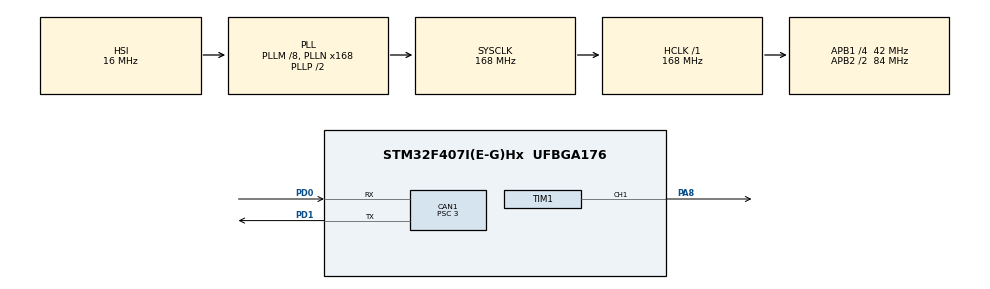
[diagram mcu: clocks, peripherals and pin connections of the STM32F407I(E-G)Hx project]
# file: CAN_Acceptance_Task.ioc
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CAN1.ABOM=ENABLE
CAN1.BS1=CAN_BS1_12TQ
CAN1.CalculateBaudRate=1000000
CAN1.CalculateTimeBit=1000
CAN1.CalculateTimeQuantum=71.42857142857143
CAN1.Prescaler=3
Mcu.Family=STM32F4
Mcu.Name=STM32F407I(E-G)Hx
Mcu.Package=UFBGA176
NVIC.CAN1_RX0_IRQn=true\:0\:0\:false\:false\:true\:true\:true\:true
NVIC.CAN1_TX_IRQn=true\:0\:0\:false\:false\:true\:true\:true\:true
NVIC.PriorityGroup=NVIC_PRIORITYGROUP_4
PA13.Mode=Serial_Wire
PA13.Signal=SYS_JTMS-SWDIO
PA14.Mode=Serial_Wire
PA14.Signal=SYS_JTCK-SWCLK
PA8.Signal=S_TIM1_CH1
PD0.Mode=CAN_Activate
PD0.Signal=CAN1_RX
PD1.Mode=CAN_Activate
PD1.Signal=CAN1_TX
PH0-OSC_IN.Mode=HSE-External-Oscillator
PH0-OSC_IN.Signal=RCC_OSC_IN
PH1-OSC_OUT.Mode=HSE-External-Oscillator
PH1-OSC_OUT.Signal=RCC_OSC_OUT
ProjectManager.HeapSize=0x200
ProjectManager.StackSize=0x400
ProjectManager.TargetToolchain=MDK-ARM V5.32
RCC.48MHZClocksFreq_Value=84000000
RCC.AHBFreq_Value=168000000
RCC.APB1CLKDivider=RCC_HCLK_DIV4
RCC.APB1Freq_Value=42000000
RCC.APB1TimFreq_Value=84000000
RCC.APB2CLKDivider=RCC_HCLK_DIV2
RCC.APB2Freq_Value=84000000
RCC.APB2TimFreq_Value=168000000
RCC.CortexFreq_Value=168000000
RCC.HCLKFreq_Value=168000000
RCC.HSE_VALUE=25000000
RCC.HSI_VALUE=16000000
RCC.LSE_VALUE=32768
RCC.PLLM=8
RCC.PLLN=168
RCC.SYSCLKFreq_VALUE=168000000
RCC.SYSCLKSource=RCC_SYSCLKSOURCE_PLLCLK
RCC.VCOOutputFreq_Value=336000000
SH.S_TIM1_CH1.0=TIM1_CH1,PWM Generation1 CH1
TIM1.Channel-PWM\ Generation1\ CH1=TIM_CHANNEL_1
VP_TIM1_VS_ClockSourceINT.Mode=Internal
board=custom

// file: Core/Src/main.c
/* USER CODE BEGIN Header */
/**
  ******************************************************************************
  * @file           : main.c
  * @brief          : Main program body
  ******************************************************************************
  * @attention
  *
  * Copyright (c) 2026 STMicroelectronics.
  * All rights reserved.
  *
  * This software is licensed under terms that can be found in the LICENSE file
  * in the root directory of this software component.
  * If no LICENSE file comes with this software, it is provided AS-IS.
  *
  ******************************************************************************
  */
/* USER CODE END Header */
#include "main.h"
#include "can.h"
#include "tim.h"
#include "gpio.h"

/* USER CODE BEGIN Includes */
#include "gm6020.h"
#include "pid.h"
#include "math.h"
/* USER CODE END Includes */

/* USER CODE BEGIN PD */
#define USE_FIXED_SPEED // 定义这个宏, 使用固定速度测试PID控制器; 注释掉这个宏, 使用正弦函数模拟目标速度的变化, 测试PID控制器在动态目标下的表现
#define INTERGRAL_MAX 10000.0f // PID积分限幅
#define OUTPUT_MAX 50000.0f // PID输出限幅

/* PID参数设置 */
#define KP 15.0f // 比例增益
#define KI 1.0f // 积分增益
#define KD 0.00f // 微分增益
/* 控制周期（单位：ms）
 * 建议1ms，和电机反馈频率匹配
 * 如果改这个值，Ki需要同步调整（Ki_new = Ki_old × 新周期/旧周期）*/
#define CONTROL_PERIOD  1

/* USER CODE END PD */

/* USER CODE BEGIN PV */
PID_T pid_speed; // 定义一个PID控制器实例, 用于速度控制
  float target_speed = 0.0f; // 目标速度, 单位为RPM

/* USER CODE END PV */

void SystemClock_Config(void);

/* USER CODE BEGIN 0 */
float Target_Speed_Sin( )
{
  /* 模拟正弦波 */
  float frequency = 50.0f;
  float result = 100.0f * sin( 2.0f * 3.14f * frequency * ( HAL_GetTick() ) / 1000.0f );
  return result;
}
/* USER CODE END 0 */

int main(void)
{

  /* MCU Configuration--------------------------------------------------------*/

  /* Reset of all peripherals, Initializes the Flash interface and the Systick. */
  HAL_Init();

  /* Configure the system clock */
  SystemClock_Config();

  /* Initialize all configured peripherals */
  MX_GPIO_Init();
  MX_CAN1_Init();
  MX_TIM1_Init();
  /* USER CODE BEGIN 2 */
  GM6020_CAN_Init(); // CAN初始化, 内部完成配置滤波器, 使能CAN, 开启中断回调
  PID_Init(&pid_speed, KP, KI, KD, INTERGRAL_MAX, OUTPUT_MAX); // 初始化PID控制器
  uint8_t flag = 1;
  /* USER CODE END 2 */

  /* Infinite loop */
  /* USER CODE BEGIN WHILE */
  while (1)
  {

    // GM6020_Set_Voltage_5TO7(3000, 3000, 3000); // 测试一下是否能够正常控制电机电压

    // GM6020_Set_Voltage_1TO4(0, 3000, 3000, 3000); // 测试一下是否能够正常控制电机电压
    if( GM6020_IsOnline(1, 500) == OFFLINE ) flag = 0; // 检测电机是否在线, flag = 0 表示电机不在线, flag = 1 表示电机在线
    else flag = 1;
    float actual_speed = (float)gm6020[1].speed; // 获取电机1的实际速度, 单位为RPM
#ifdef USE_FIXED_SPEED
    target_speed = 100.0f; // 固定目标速度
#else
    target_speed = Target_Speed_Sin(); // 模拟正弦波作为目标速度
#endif
    float voltage = PID_Calculate(&pid_speed, target_speed, actual_speed); // 计算PID控制器输出的电压值
    GM6020_Set_Voltage_1TO4(voltage, 0 ,0, voltage); // 输出电压控制电机1, 电机2-4不控制
    HAL_Delay(CONTROL_PERIOD); // 控制周期, 建议1ms, 和电机反馈频率匹配
    /* USER CODE END WHILE */

  }
}

void SystemClock_Config(void)
{
  RCC_OscInitTypeDef RCC_OscInitStruct = {0};
  RCC_ClkInitTypeDef RCC_ClkInitStruct = {0};

  /** Configure the main internal regulator output voltage
  */
  __HAL_RCC_PWR_CLK_ENABLE();
  __HAL_PWR_VOLTAGESCALING_CONFIG(PWR_REGULATOR_VOLTAGE_SCALE1);

  /** Initializes the RCC Oscillators according to the specified parameters
  * in the RCC_OscInitTypeDef structure.
  */
  RCC_OscInitStruct.OscillatorType = RCC_OSCILLATORTYPE_HSI;
  RCC_OscInitStruct.HSIState = RCC_HSI_ON;
  RCC_OscInitStruct.HSICalibrationValue = RCC_HSICALIBRATION_DEFAULT;
  RCC_OscInitStruct.PLL.PLLState = RCC_PLL_ON;
  RCC_OscInitStruct.PLL.PLLSource = RCC_PLLSOURCE_HSI;
  RCC_OscInitStruct.PLL.PLLM = 8;
  RCC_OscInitStruct.PLL.PLLN = 168;
  RCC_OscInitStruct.PLL.PLLP = RCC_PLLP_DIV2;
  RCC_OscInitStruct.PLL.PLLQ = 4;
  if (HAL_RCC_OscConfig(&RCC_OscInitStruct) != HAL_OK)
  {
    Error_Handler();
  }

  /** Initializes the CPU, AHB and APB buses clocks
  */
  RCC_ClkInitStruct.ClockType = RCC_CLOCKTYPE_HCLK|RCC_CLOCKTYPE_SYSCLK
                              |RCC_CLOCKTYPE_PCLK1|RCC_CLOCKTYPE_PCLK2;
  RCC_ClkInitStruct.SYSCLKSource = RCC_SYSCLKSOURCE_PLLCLK;
  RCC_ClkInitStruct.AHBCLKDivider = RCC_SYSCLK_DIV1;
  RCC_ClkInitStruct.APB1CLKDivider = RCC_HCLK_DIV4;
  RCC_ClkInitStruct.APB2CLKDivider = RCC_HCLK_DIV2;

  if (HAL_RCC_ClockConfig(&RCC_ClkInitStruct, FLASH_LATENCY_5) != HAL_OK)
  {
    Error_Handler();
  }
}

void Error_Handler(void)
{
  __disable_irq();
  while (1)
  {
  }
}
